# TM4C129ENCPDT register map
File version: 1.0
CPU: CORTEX_M4 1.0, other endian, MPU, FPU, 3 interrupt priority bits
Registers are 32-bit, read-write, reset 0x0 unless marked. A register's access mark holds for its fields unless they carry their own. Offsets are from the block's base; [hi:lo] are bit positions; {n}, {i} and the like mark numbered series.

## USB0 — Univeral Serial Bus register offsets
Base 0x40050000
0x00 USB_FADDR 8-bit — USB Device Functional Address
  [6:0] USB_FADDR — [6:0] Function Address
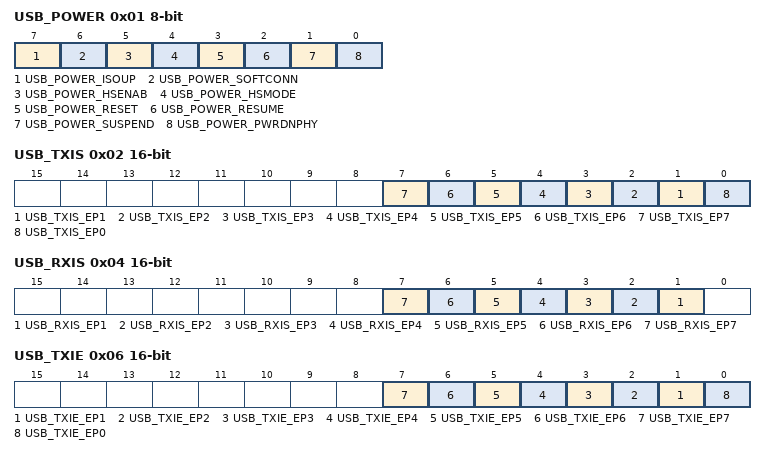
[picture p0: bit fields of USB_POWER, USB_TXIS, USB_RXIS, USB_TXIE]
0x01 USB_POWER 8-bit
  [7] USB_POWER_ISOUP — [7:7] Isochronous Update
  [6] USB_POWER_SOFTCONN — [6:6] Soft Connect/Disconnect
  [5] USB_POWER_HSENAB — [5:5] High Speed Enable
  [4] USB_POWER_HSMODE — [4:4] High Speed Enable
  [3] USB_POWER_RESET — [3:3] RESET Signaling
  [2] USB_POWER_RESUME — [2:2] RESUME Signaling
  [1] USB_POWER_SUSPEND — [1:1] SUSPEND Mode
  [0] USB_POWER_PWRDNPHY — [0:0] Power Down PHY
0x02 USB_TXIS 16-bit — USB Transmit Interrupt Status
  [n] USB_TXIS_EP{n} (n=1..7) — [{n}:{n}] TX Endpoint {n} Interrupt
  [0] USB_TXIS_EP0 — [0:0] TX and RX Endpoint 0 Interrupt
0x04 USB_RXIS 16-bit — USB Receive Interrupt Status
  [n] USB_RXIS_EP{n} (n=1..7) — [{n}:{n}] RX Endpoint {n} Interrupt
0x06 USB_TXIE 16-bit — USB Transmit Interrupt Enable
  [n] USB_TXIE_EP{n} (n=1..7) — [{n}:{n}] TX Endpoint {n} Interrupt Enable
  [0] USB_TXIE_EP0 — [0:0] TX and RX Endpoint 0 Interrupt Enable
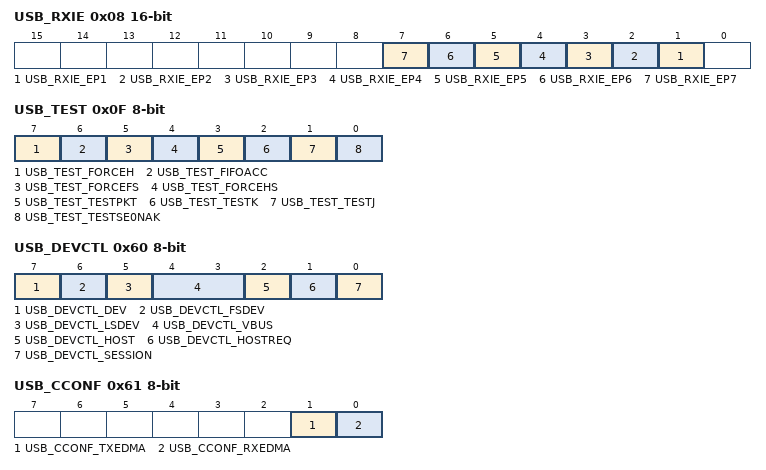
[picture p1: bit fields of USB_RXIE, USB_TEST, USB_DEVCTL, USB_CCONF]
0x08 USB_RXIE 16-bit — USB Receive Interrupt Enable
  [n] USB_RXIE_EP{n} (n=1..7) — [{n}:{n}] RX Endpoint {n} Interrupt Enable
0x0A USB_IS 8-bit — USB General Interrupt Status
  [7] USB_IS_VBUSERR — [7:7] VBUS Error (OTG only)
  [6] USB_IS_SESREQ — [6:6] SESSION REQUEST (OTG only)
  [5] USB_IS_DISCON — [5:5] Session Disconnect (OTG only)
  [4] USB_IS_CONN — [4:4] Session Connect
  [3] USB_IS_SOF — [3:3] Start of Frame
  [2] USB_IS_BABBLE — [2:2] Babble Detected
  [2] USB_IS_RESET — [2:2] RESET Signaling Detected
  [1] USB_IS_RESUME — [1:1] RESUME Signaling Detected
  [0] USB_IS_SUSPEND — [0:0] SUSPEND Signaling Detected
0x0B USB_IE 8-bit — USB Interrupt Enable
  [7] USB_IE_VBUSERR — [7:7] Enable VBUS Error Interrupt (OTG only)
  [6] USB_IE_SESREQ — [6:6] Enable Session Request (OTG only)
  [5] USB_IE_DISCON — [5:5] Enable Disconnect Interrupt
  [4] USB_IE_CONN — [4:4] Enable Connect Interrupt
  [3] USB_IE_SOF — [3:3] Enable Start-of-Frame Interrupt
  [2] USB_IE_BABBLE — [2:2] Enable Babble Interrupt
  [2] USB_IE_RESET — [2:2] Enable RESET Interrupt
  [1] USB_IE_RESUME — [1:1] Enable RESUME Interrupt
  [0] USB_IE_SUSPND — [0:0] Enable SUSPEND Interrupt
0x0C USB_FRAME 16-bit — USB Frame Value
  [10:0] USB_FRAME — [10:0] Frame Number
0x0E USB_EPIDX 8-bit — USB Endpoint Index
  [3:0] USB_EPIDX_EPIDX — [3:0] Endpoint Index
0x0F USB_TEST 8-bit — USB Test Mode
  [7] USB_TEST_FORCEH — [7:7] Force Host Mode
  [6] USB_TEST_FIFOACC — [6:6] FIFO Access
  [5] USB_TEST_FORCEFS — [5:5] Force Full-Speed Mode
  [4] USB_TEST_FORCEHS — [4:4] Force High-Speed Mode
  [3] USB_TEST_TESTPKT — [3:3] Test Packet Mode Enable
  [2] USB_TEST_TESTK — [2:2] Test_K Mode Enable
  [1] USB_TEST_TESTJ — [1:1] Test_J Mode Enable
  [0] USB_TEST_TESTSE0NAK — [0:0] Test_SE0_NAK Test Mode Enable
{0x20+4i} USB_FIFO{i} (i=0..7) — USB FIFO Endpoint {i}
  [31:0] USB_FIFO{i}_EPDATA — [31:0] Endpoint Data
0x60 USB_DEVCTL 8-bit — USB Device Control
  [7] USB_DEVCTL_DEV — [7:7] Device Mode (OTG only)
  [6] USB_DEVCTL_FSDEV — [6:6] Full-Speed Device Detected
  [5] USB_DEVCTL_LSDEV — [5:5] Low-Speed Device Detected
  [4:3] USB_DEVCTL_VBUS — [4:3] VBUS Level (OTG only)
    0=USB_DEVCTL_VBUS_NONE (Below SessionEnd); 8=USB_DEVCTL_VBUS_SEND (Above SessionEnd, below AValid); 16=USB_DEVCTL_VBUS_AVALID (Above AValid, below VBUSValid); 24=USB_DEVCTL_VBUS_VALID (Above VBUSValid)
  [2] USB_DEVCTL_HOST — [2:2] Host Mode
  [1] USB_DEVCTL_HOSTREQ — [1:1] Host Request (OTG only)
  [0] USB_DEVCTL_SESSION — [0:0] Session Start/End (OTG only)
0x61 USB_CCONF 8-bit — USB Common Configuration
  [1] USB_CCONF_TXEDMA — [1:1] TX Early DMA Enable
  [0] USB_CCONF_RXEDMA — [0:0] TX Early DMA Enable
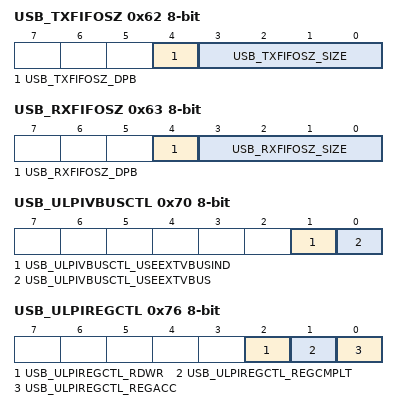
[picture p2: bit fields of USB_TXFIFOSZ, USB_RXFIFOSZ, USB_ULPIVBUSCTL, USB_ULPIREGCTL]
0x62 USB_TXFIFOSZ 8-bit — USB Transmit Dynamic FIFO Sizing
  [4] USB_TXFIFOSZ_DPB — [4:4] Double Packet Buffer Support
  [3:0] USB_TXFIFOSZ_SIZE — [3:0] Max Packet Size
    0=8; 1=16; 2=32; 3=64; 4=128; 5=256; 6=512; 7=1024; 8=2048
0x63 USB_RXFIFOSZ 8-bit — USB Receive Dynamic FIFO Sizing
  [4] USB_RXFIFOSZ_DPB — [4:4] Double Packet Buffer Support
  [3:0] USB_RXFIFOSZ_SIZE — [3:0] Max Packet Size
    0=8; 1=16; 2=32; 3=64; 4=128; 5=256; 6=512; 7=1024; 8=2048
0x64 USB_TXFIFOADD 16-bit — USB Transmit FIFO Start Address
  [8:0] USB_TXFIFOADD_ADDR — [8:0] Transmit/Receive Start Address
0x66 USB_RXFIFOADD 16-bit — USB Receive FIFO Start Address
  [8:0] USB_RXFIFOADD_ADDR — [8:0] Transmit/Receive Start Address
0x70 USB_ULPIVBUSCTL 8-bit — USB ULPI VBUS Control
  [1] USB_ULPIVBUSCTL_USEEXTVBUSIND — [1:1] Use External VBUS Indicator
  [0] USB_ULPIVBUSCTL_USEEXTVBUS — [0:0] Use External VBUS
0x74 USB_ULPIREGDATA 8-bit — USB ULPI Register Data
  [7:0] USB_ULPIREGDATA_REGDATA — [7:0] Register Data
0x75 USB_ULPIREGADDR 8-bit — USB ULPI Register Address
  [7:0] USB_ULPIREGADDR_ADDR — [7:0] Register Address
0x76 USB_ULPIREGCTL 8-bit — USB ULPI Register Control
  [2] USB_ULPIREGCTL_RDWR — [2:2] Read/Write Control
  [1] USB_ULPIREGCTL_REGCMPLT — [1:1] Register Access Complete
  [0] USB_ULPIREGCTL_REGACC — [0:0] Initiate Register Access
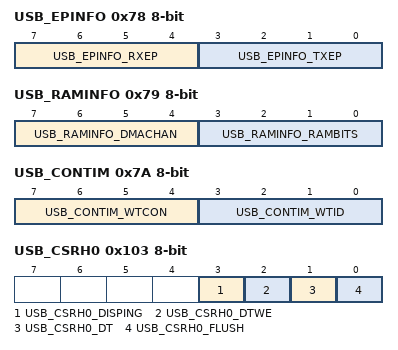
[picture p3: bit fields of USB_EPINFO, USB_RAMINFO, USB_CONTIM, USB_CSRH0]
0x78 USB_EPINFO 8-bit — USB Endpoint Information
  [7:4] USB_EPINFO_RXEP — [7:4] RX Endpoints
  [3:0] USB_EPINFO_TXEP — [3:0] TX Endpoints
0x79 USB_RAMINFO 8-bit — USB RAM Information
  [7:4] USB_RAMINFO_DMACHAN — [7:4] DMA Channels
  [3:0] USB_RAMINFO_RAMBITS — [3:0] RAM Address Bus Width
0x7A USB_CONTIM 8-bit — USB Connect Timing
  [7:4] USB_CONTIM_WTCON — [7:4] Connect Wait
  [3:0] USB_CONTIM_WTID — [3:0] Wait ID
0x7B USB_VPLEN 8-bit — USB OTG VBUS Pulse Timing
  [7:0] USB_VPLEN_VPLEN — [7:0] VBUS Pulse Length
0x7C USB_HSEOF 8-bit — USB High-Speed Last Transaction to End of Frame Timing
  [7:0] USB_HSEOF_HSEOFG — [7:0] HIgh-Speed End-of-Frame Gap
0x7D USB_FSEOF 8-bit — USB Full-Speed Last Transaction to End of Frame Timing
  [7:0] USB_FSEOF_FSEOFG — [7:0] Full-Speed End-of-Frame Gap
0x7E USB_LSEOF 8-bit — USB Low-Speed Last Transaction to End of Frame Timing
  [7:0] USB_LSEOF_LSEOFG — [7:0] Low-Speed End-of-Frame Gap
{0x80+8i} USB_TXFUNCADDR{i} 8-bit (i=0..7) — USB Transmit Functional Address Endpoint {i}
  [6:0] USB_TXFUNCADDR{i}_ADDR — [6:0] Device Address
{0x82+8i} USB_TXHUBADDR{i} 8-bit (i=0..7) — USB Transmit Hub Address Endpoint {i}
  [6:0] USB_TXHUBADDR{i}_ADDR — [6:0] Hub Address
{0x83+8i} USB_TXHUBPORT{i} 8-bit (i=0..7) — USB Transmit Hub Port Endpoint {i}
  [6:0] USB_TXHUBPORT{i}_PORT — [6:0] Hub Port
{0x84+8i} USB_RXFUNCADDR{i} 8-bit (i=1..7) — USB Receive Functional Address Endpoint {i}
  [6:0] USB_RXFUNCADDR{i}_ADDR — [6:0] Device Address
{0x86+8i} USB_RXHUBADDR{i} 8-bit (i=1..7) — USB Receive Hub Address Endpoint {i}
  [6:0] USB_RXHUBADDR{i}_ADDR — [6:0] Hub Address
{0x87+8i} USB_RXHUBPORT{i} 8-bit (i=1..7) — USB Receive Hub Port Endpoint {i}
  [6:0] USB_RXHUBPORT{i}_PORT — [6:0] Hub Port
0x102 USB_CSRL0 8-bit — USB Control and Status Endpoint 0 Low
  [7] USB_CSRL0_NAKTO — [7:7] NAK Timeout
  [7] USB_CSRL0_SETENDC — [7:7] Setup End Clear
  [6] USB_CSRL0_STATUS — [6:6] STATUS Packet
  [6] USB_CSRL0_RXRDYC — [6:6] RXRDY Clear
  [5] USB_CSRL0_REQPKT — [5:5] Request Packet
  [5] USB_CSRL0_STALL — [5:5] Send Stall
  [4] USB_CSRL0_SETEND — [4:4] Setup End
  [4] USB_CSRL0_ERROR — [4:4] Error
  [3] USB_CSRL0_DATAEND — [3:3] Data End
  [3] USB_CSRL0_SETUP — [3:3] Setup Packet
  [2] USB_CSRL0_STALLED — [2:2] Endpoint Stalled
  [1] USB_CSRL0_TXRDY — [1:1] Transmit Packet Ready
  [0] USB_CSRL0_RXRDY — [0:0] Receive Packet Ready
0x103 USB_CSRH0 8-bit — USB Control and Status Endpoint 0 High
  [3] USB_CSRH0_DISPING — [3:3] PING Disable
  [2] USB_CSRH0_DTWE — [2:2] Data Toggle Write Enable
  [1] USB_CSRH0_DT — [1:1] Data Toggle
  [0] USB_CSRH0_FLUSH — [0:0] Flush FIFO
0x108 USB_COUNT0 8-bit — USB Receive Byte Count Endpoint 0
  [6:0] USB_COUNT0_COUNT — [6:0] FIFO Count
0x10A USB_TYPE0 8-bit — USB Type Endpoint 0
  [7:6] USB_TYPE0_SPEED — [7:6] Operating Speed
    64=USB_TYPE0_SPEED_HIGH (High); 128=USB_TYPE0_SPEED_FULL (Full); 192=USB_TYPE0_SPEED_LOW (Low)
0x10B USB_NAKLMT 8-bit — USB NAK Limit
  [4:0] USB_NAKLMT_NAKLMT — [4:0] EP0 NAK Limit
{0x100+0x10*i} USB_TXMAXP{i} 16-bit (i=1..7) — USB Maximum Transmit Data Endpoint {i}
  [10:0] USB_TXMAXP{i}_MAXLOAD — [10:0] Maximum Payload
0x112 USB_TXCSRL1 8-bit — USB Transmit Control and Status Endpoint 1 Low
  [7] USB_TXCSRL1_NAKTO — [7:7] NAK Timeout
  [6] USB_TXCSRL1_CLRDT — [6:6] Clear Data Toggle
  [5] USB_TXCSRL1_STALLED — [5:5] Endpoint Stalled
  [4] USB_TXCSRL1_STALL — [4:4] Send STALL
  [4] USB_TXCSRL1_SETUP — [4:4] Setup Packet
  [3] USB_TXCSRL1_FLUSH — [3:3] Flush FIFO
  [2] USB_TXCSRL1_ERROR — [2:2] Error
  [2] USB_TXCSRL1_UNDRN — [2:2] Underrun
  [1] USB_TXCSRL1_FIFONE — [1:1] FIFO Not Empty
  [0] USB_TXCSRL1_TXRDY — [0:0] Transmit Packet Ready
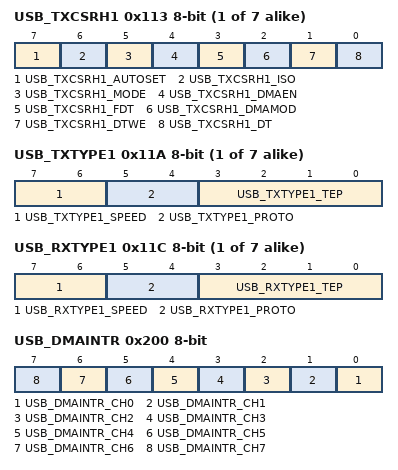
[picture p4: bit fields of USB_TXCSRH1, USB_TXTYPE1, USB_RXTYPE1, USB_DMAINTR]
{0x103+0x10*i} USB_TXCSRH{i} 8-bit (i=1..7) — USB Transmit Control and Status Endpoint {i} High
  [7] USB_TXCSRH{i}_AUTOSET — [7:7] Auto Set
  [6] USB_TXCSRH{i}_ISO — [6:6] Isochronous Transfers
  [5] USB_TXCSRH{i}_MODE — [5:5] Mode
  [4] USB_TXCSRH{i}_DMAEN — [4:4] DMA Request Enable
  [3] USB_TXCSRH{i}_FDT — [3:3] Force Data Toggle
  [2] USB_TXCSRH{i}_DMAMOD — [2:2] DMA Request Mode
  [1] USB_TXCSRH{i}_DTWE — [1:1] Data Toggle Write Enable
  [0] USB_TXCSRH{i}_DT — [0:0] Data Toggle
{0x104+0x10*i} USB_RXMAXP{i} 16-bit (i=1..7) — USB Maximum Receive Data Endpoint {i}
  [10:0] USB_RXMAXP{i}_MAXLOAD — [10:0] Maximum Payload
0x116 USB_RXCSRL1 8-bit — USB Receive Control and Status Endpoint 1 Low
  [7] USB_RXCSRL1_CLRDT — [7:7] Clear Data Toggle
  [6] USB_RXCSRL1_STALLED — [6:6] Endpoint Stalled
  [5] USB_RXCSRL1_STALL — [5:5] Send STALL
  [5] USB_RXCSRL1_REQPKT — [5:5] Request Packet
  [4] USB_RXCSRL1_FLUSH — [4:4] Flush FIFO
  [3] USB_RXCSRL1_DATAERR — [3:3] Data Error
  [3] USB_RXCSRL1_NAKTO — [3:3] NAK Timeout
  [2] USB_RXCSRL1_OVER — [2:2] Overrun
  [2] USB_RXCSRL1_ERROR — [2:2] Error
  [1] USB_RXCSRL1_FULL — [1:1] FIFO Full
  [0] USB_RXCSRL1_RXRDY — [0:0] Receive Packet Ready
{0x107+0x10*i} USB_RXCSRH{i} 8-bit (i=1..6) — USB Receive Control and Status Endpoint {i} High
  [7] USB_RXCSRH{i}_AUTOCL — [7:7] Auto Clear
  [6] USB_RXCSRH{i}_AUTORQ — [6:6] Auto Request
  [6] USB_RXCSRH{i}_ISO — [6:6] Isochronous Transfers
  [5] USB_RXCSRH{i}_DMAEN — [5:5] DMA Request Enable
  [4] USB_RXCSRH{i}_DISNYET — [4:4] Disable NYET
  [4] USB_RXCSRH{i}_PIDERR — [4:4] PID Error
  [3] USB_RXCSRH{i}_DMAMOD — [3:3] DMA Request Mode
  [2] USB_RXCSRH{i}_DTWE — [2:2] Data Toggle Write Enable
  [1] USB_RXCSRH{i}_DT — [1:1] Data Toggle
  [0] USB_RXCSRH{i}_INCOMPRX — [0:0] Incomplete RX Transmission Status
{0x108+0x10*i} USB_RXCOUNT{i} 16-bit (i=1..7) — USB Receive Byte Count Endpoint {i}
  [12:0] USB_RXCOUNT{i}_COUNT — [12:0] Receive Packet Count
{0x10A+0x10*i} USB_TXTYPE{i} 8-bit (i=1..7) — USB Host Transmit Configure Type Endpoint {i}
  [7:6] USB_TXTYPE{i}_SPEED — [7:6] Operating Speed
    0=USB_TXTYPE{i}_SPEED_DFLT (Default); 64=USB_TXTYPE{i}_SPEED_HIGH (High); 128=USB_TXTYPE{i}_SPEED_FULL (Full); 192=USB_TXTYPE{i}_SPEED_LOW (Low)
  [5:4] USB_TXTYPE{i}_PROTO — [5:4] Protocol
    0=USB_TXTYPE{i}_PROTO_CTRL (Control); 16=USB_TXTYPE{i}_PROTO_ISOC (Isochronous); 32=USB_TXTYPE{i}_PROTO_BULK (Bulk); 48=USB_TXTYPE{i}_PROTO_INT (Interrupt)
  [3:0] USB_TXTYPE{i}_TEP — [3:0] Target Endpoint Number
{0x10B+0x10*i} USB_TXINTERVAL{i} 8-bit (i=1..7) — USB Host Transmit Interval Endpoint {i}
  [7:0] USB_TXINTERVAL{i}_TXPOLL — [7:0] TX Polling
{0x10B+0x10*i} USB_TXINTERVAL{i}_ 8-bit (i=1..7) — USB Host Transmit Interval Endpoint {i}
  [7:0] USB_TXINTERVAL{i}_NAKLMT — [7:0] NAK Limit
{0x10C+0x10*i} USB_RXTYPE{i} 8-bit (i=1..7) — USB Host Configure Receive Type Endpoint {i}
  [7:6] USB_RXTYPE{i}_SPEED — [7:6] Operating Speed
    0=USB_RXTYPE{i}_SPEED_DFLT (Default); 64=USB_RXTYPE{i}_SPEED_HIGH (High); 128=USB_RXTYPE{i}_SPEED_FULL (Full); 192=USB_RXTYPE{i}_SPEED_LOW (Low)
  [5:4] USB_RXTYPE{i}_PROTO — [5:4] Protocol
    0=USB_RXTYPE{i}_PROTO_CTRL (Control); 16=USB_RXTYPE{i}_PROTO_ISOC (Isochronous); 32=USB_RXTYPE{i}_PROTO_BULK (Bulk); 48=USB_RXTYPE{i}_PROTO_INT (Interrupt)
  [3:0] USB_RXTYPE{i}_TEP — [3:0] Target Endpoint Number
{0x10D+0x10*i} USB_RXINTERVAL{i} 8-bit (i=1..7) — USB Host Receive Polling Interval Endpoint {i}
  [7:0] USB_RXINTERVAL{i}_TXPOLL — [7:0] RX Polling
{0x10D+0x10*i} USB_RXINTERVAL{i}_ 8-bit (i=1..7) — USB Host Receive Polling Interval Endpoint {i}
  [7:0] USB_RXINTERVAL{i}_NAKLMT — [7:0] NAK Limit
{0x102+0x10*i} USB_TXCSRL{i} 8-bit (i=2..5) — USB Transmit Control and Status Endpoint {i} Low
  [7] USB_TXCSRL{i}_NAKTO — [7:7] NAK Timeout
  [6] USB_TXCSRL{i}_CLRDT — [6:6] Clear Data Toggle
  [5] USB_TXCSRL{i}_STALLED — [5:5] Endpoint Stalled
  [4] USB_TXCSRL{i}_SETUP — [4:4] Setup Packet
  [4] USB_TXCSRL{i}_STALL — [4:4] Send STALL
  [3] USB_TXCSRL{i}_FLUSH — [3:3] Flush FIFO
  [2] USB_TXCSRL{i}_ERROR — [2:2] Error
  [2] USB_TXCSRL{i}_UNDRN — [2:2] Underrun
  [1] USB_TXCSRL{i}_FIFONE — [1:1] FIFO Not Empty
  [0] USB_TXCSRL{i}_TXRDY — [0:0] Transmit Packet Ready
0x126 USB_RXCSRL2 8-bit — USB Receive Control and Status Endpoint 2 Low
  [7] USB_RXCSRL2_CLRDT — [7:7] Clear Data Toggle
  [6] USB_RXCSRL2_STALLED — [6:6] Endpoint Stalled
  [5] USB_RXCSRL2_REQPKT — [5:5] Request Packet
  [5] USB_RXCSRL2_STALL — [5:5] Send STALL
  [4] USB_RXCSRL2_FLUSH — [4:4] Flush FIFO
  [3] USB_RXCSRL2_DATAERR — [3:3] Data Error
  [3] USB_RXCSRL2_NAKTO — [3:3] NAK Timeout
  [2] USB_RXCSRL2_ERROR — [2:2] Error
  [2] USB_RXCSRL2_OVER — [2:2] Overrun
  [1] USB_RXCSRL2_FULL — [1:1] FIFO Full
  [0] USB_RXCSRL2_RXRDY — [0:0] Receive Packet Ready
0x136 USB_RXCSRL3 8-bit — USB Receive Control and Status Endpoint 3 Low
  [7] USB_RXCSRL3_CLRDT — [7:7] Clear Data Toggle
  [6] USB_RXCSRL3_STALLED — [6:6] Endpoint Stalled
  [5] USB_RXCSRL3_STALL — [5:5] Send STALL
  [5] USB_RXCSRL3_REQPKT — [5:5] Request Packet
  [4] USB_RXCSRL3_FLUSH — [4:4] Flush FIFO
  [3] USB_RXCSRL3_DATAERR — [3:3] Data Error
  [3] USB_RXCSRL3_NAKTO — [3:3] NAK Timeout
  [2] USB_RXCSRL3_ERROR — [2:2] Error
  [2] USB_RXCSRL3_OVER — [2:2] Overrun
  [1] USB_RXCSRL3_FULL — [1:1] FIFO Full
  [0] USB_RXCSRL3_RXRDY — [0:0] Receive Packet Ready
0x146 USB_RXCSRL4 8-bit — USB Receive Control and Status Endpoint 4 Low
  [7] USB_RXCSRL4_CLRDT — [7:7] Clear Data Toggle
  [6] USB_RXCSRL4_STALLED — [6:6] Endpoint Stalled
  [5] USB_RXCSRL4_STALL — [5:5] Send STALL
  [5] USB_RXCSRL4_REQPKT — [5:5] Request Packet
  [4] USB_RXCSRL4_FLUSH — [4:4] Flush FIFO
  [3] USB_RXCSRL4_NAKTO — [3:3] NAK Timeout
  [3] USB_RXCSRL4_DATAERR — [3:3] Data Error
  [2] USB_RXCSRL4_OVER — [2:2] Overrun
  [2] USB_RXCSRL4_ERROR — [2:2] Error
  [1] USB_RXCSRL4_FULL — [1:1] FIFO Full
  [0] USB_RXCSRL4_RXRDY — [0:0] Receive Packet Ready
0x156 USB_RXCSRL5 8-bit — USB Receive Control and Status Endpoint 5 Low
  [7] USB_RXCSRL5_CLRDT — [7:7] Clear Data Toggle
  [6] USB_RXCSRL5_STALLED — [6:6] Endpoint Stalled
  [5] USB_RXCSRL5_STALL — [5:5] Send STALL
  [5] USB_RXCSRL5_REQPKT — [5:5] Request Packet
  [4] USB_RXCSRL5_FLUSH — [4:4] Flush FIFO
  [3] USB_RXCSRL5_NAKTO — [3:3] NAK Timeout
  [3] USB_RXCSRL5_DATAERR — [3:3] Data Error
  [2] USB_RXCSRL5_ERROR — [2:2] Error
  [2] USB_RXCSRL5_OVER — [2:2] Overrun
  [1] USB_RXCSRL5_FULL — [1:1] FIFO Full
  [0] USB_RXCSRL5_RXRDY — [0:0] Receive Packet Ready
0x162 USB_TXCSRL6 8-bit — USB Transmit Control and Status Endpoint 6 Low
  [7] USB_TXCSRL6_NAKTO — [7:7] NAK Timeout
  [6] USB_TXCSRL6_CLRDT — [6:6] Clear Data Toggle
  [5] USB_TXCSRL6_STALLED — [5:5] Endpoint Stalled
  [4] USB_TXCSRL6_STALL — [4:4] Send STALL
  [4] USB_TXCSRL6_SETUP — [4:4] Setup Packet
  [3] USB_TXCSRL6_FLUSH — [3:3] Flush FIFO
  [2] USB_TXCSRL6_ERROR — [2:2] Error
  [2] USB_TXCSRL6_UNDRN — [2:2] Underrun
  [1] USB_TXCSRL6_FIFONE — [1:1] FIFO Not Empty
  [0] USB_TXCSRL6_TXRDY — [0:0] Transmit Packet Ready
0x166 USB_RXCSRL6 8-bit — USB Receive Control and Status Endpoint 6 Low
  [7] USB_RXCSRL6_CLRDT — [7:7] Clear Data Toggle
  [6] USB_RXCSRL6_STALLED — [6:6] Endpoint Stalled
  [5] USB_RXCSRL6_REQPKT — [5:5] Request Packet
  [5] USB_RXCSRL6_STALL — [5:5] Send STALL
  [4] USB_RXCSRL6_FLUSH — [4:4] Flush FIFO
  [3] USB_RXCSRL6_NAKTO — [3:3] NAK Timeout
  [3] USB_RXCSRL6_DATAERR — [3:3] Data Error
  [2] USB_RXCSRL6_ERROR — [2:2] Error
  [2] USB_RXCSRL6_OVER — [2:2] Overrun
  [1] USB_RXCSRL6_FULL — [1:1] FIFO Full
  [0] USB_RXCSRL6_RXRDY — [0:0] Receive Packet Ready
0x172 USB_TXCSRL7 8-bit — USB Transmit Control and Status Endpoint 7 Low
  [7] USB_TXCSRL7_NAKTO — [7:7] NAK Timeout
  [6] USB_TXCSRL7_CLRDT — [6:6] Clear Data Toggle
  [5] USB_TXCSRL7_STALLED — [5:5] Endpoint Stalled
  [4] USB_TXCSRL7_STALL — [4:4] Send STALL
  [4] USB_TXCSRL7_SETUP — [4:4] Setup Packet
  [3] USB_TXCSRL7_FLUSH — [3:3] Flush FIFO
  [2] USB_TXCSRL7_ERROR — [2:2] Error
  [2] USB_TXCSRL7_UNDRN — [2:2] Underrun
  [1] USB_TXCSRL7_FIFONE — [1:1] FIFO Not Empty
  [0] USB_TXCSRL7_TXRDY — [0:0] Transmit Packet Ready
0x176 USB_RXCSRL7 8-bit — USB Receive Control and Status Endpoint 7 Low
  [7] USB_RXCSRL7_CLRDT — [7:7] Clear Data Toggle
  [6] USB_RXCSRL7_STALLED — [6:6] Endpoint Stalled
  [5] USB_RXCSRL7_REQPKT — [5:5] Request Packet
  [5] USB_RXCSRL7_STALL — [5:5] Send STALL
  [4] USB_RXCSRL7_FLUSH — [4:4] Flush FIFO
  [3] USB_RXCSRL7_DATAERR — [3:3] Data Error
  [3] USB_RXCSRL7_NAKTO — [3:3] NAK Timeout
  [2] USB_RXCSRL7_ERROR — [2:2] Error
  [2] USB_RXCSRL7_OVER — [2:2] Overrun
  [1] USB_RXCSRL7_FULL — [1:1] FIFO Full
  [0] USB_RXCSRL7_RXRDY — [0:0] Receive Packet Ready
0x177 USB_RXCSRH7 8-bit — USB Receive Control and Status Endpoint 7 High
  [7] USB_RXCSRH7_AUTOCL — [7:7] Auto Clear
  [6] USB_RXCSRH7_ISO — [6:6] Isochronous Transfers
  [6] USB_RXCSRH7_AUTORQ — [6:6] Auto Request
  [5] USB_RXCSRH7_DMAEN — [5:5] DMA Request Enable
  [4] USB_RXCSRH7_PIDERR — [4:4] PID Error
  [4] USB_RXCSRH7_DISNYET — [4:4] Disable NYET
  [3] USB_RXCSRH7_DMAMOD — [3:3] DMA Request Mode
  [2] USB_RXCSRH7_DTWE — [2:2] Data Toggle Write Enable
  [1] USB_RXCSRH7_DT — [1:1] Data Toggle
  [0] USB_RXCSRH7_INCOMPRX — [0:0] Incomplete RX Transmission Status
0x200 USB_DMAINTR 8-bit — USB DMA Interrupt
  [n] USB_DMAINTR_CH{n} (n=0..7) — [{n}:{n}] Channel {n} DMA Interrupt
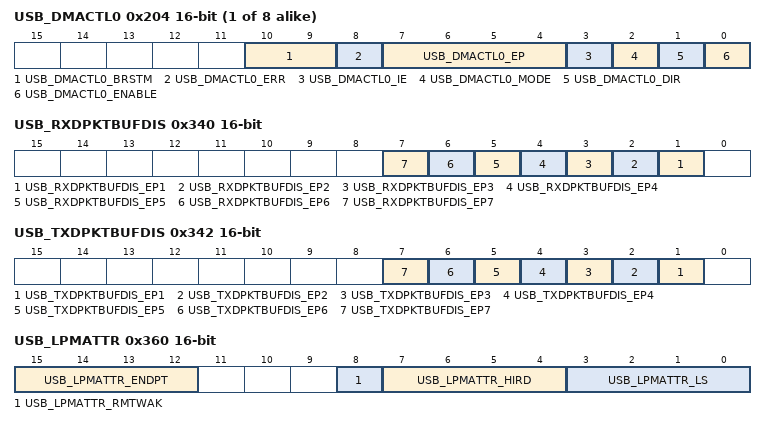
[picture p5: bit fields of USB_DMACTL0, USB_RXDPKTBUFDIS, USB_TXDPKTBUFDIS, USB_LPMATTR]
{0x204+0x10*i} USB_DMACTL{i} 16-bit (i=0..7) — USB DMA Control {i}
  [10:9] USB_DMACTL{i}_BRSTM — [10:9] Burst Mode
    0=USB_DMACTL{i}_BRSTM_ANY (Bursts of unspecified length); 0x200=USB_DMACTL{i}_BRSTM_INC4 (INCR4 or unspecified length); 0x400=USB_DMACTL{i}_BRSTM_INC8 (INCR8, INCR4 or unspecified length); 0x600=USB_DMACTL{i}_BRSTM_INC16 (INCR16, INCR8, INCR4 or unspecified length)
  [8] USB_DMACTL{i}_ERR — [8:8] Bus Error Bit
  [7:4] USB_DMACTL{i}_EP — [7:4] Endpoint number
  [3] USB_DMACTL{i}_IE — [3:3] DMA Interrupt Enable
  [2] USB_DMACTL{i}_MODE — [2:2] DMA Transfer Mode
  [1] USB_DMACTL{i}_DIR — [1:1] DMA Direction
  [0] USB_DMACTL{i}_ENABLE — [0:0] DMA Transfer Enable
{0x208+0x10*i} USB_DMAADDR{i} (i=0..7) — USB DMA Address {i}
  [31:2] USB_DMAADDR{i}_ADDR — [31:2] DMA Address
{0x20C+0x10*i} USB_DMACOUNT{i} (i=0..7)
  [31:2] USB_DMACOUNT{i}_COUNT — [31:2] DMA Count
{0x300+4i} USB_RQPKTCOUNT{i} 16-bit (i=1..3) — USB Request Packet Count in Block Transfer Endpoint {i}
  [15:0] USB_RQPKTCOUNT{i} — [15:0] Block Transfer Packet Count
{0x300+4i} USB_RQPKTCOUNT{i} 16-bit (i=4..7) — USB Request Packet Count in Block Transfer Endpoint {i}
  [15:0] USB_RQPKTCOUNT{i}_COUNT — [15:0] Block Transfer Packet Count
0x340 USB_RXDPKTBUFDIS 16-bit — USB Receive Double Packet Buffer Disable
  [n] USB_RXDPKTBUFDIS_EP{n} (n=1..7) — [{n}:{n}] EP{n} RX Double-Packet Buffer Disable
0x342 USB_TXDPKTBUFDIS 16-bit — USB Transmit Double Packet Buffer Disable
  [n] USB_TXDPKTBUFDIS_EP{n} (n=1..7) — [{n}:{n}] EP{n} TX Double-Packet Buffer Disable
0x344 USB_CTO 16-bit — USB Chirp Timeout
  [15:0] USB_CTO_CCTV — [15:0] Configurable Chirp Timeout Value
0x346 USB_HHSRTN 16-bit — USB High Speed to UTM Operating Delay
  [15:0] USB_HHSRTN_HHSRTN — [15:0] HIgh Speed to UTM Operating Delay
0x348 USB_HSBT 16-bit — USB High Speed Time-out Adder
  [3:0] USB_HSBT_HSBT — [3:0] High Speed Timeout Adder
0x360 USB_LPMATTR 16-bit — USB LPM Attributes
  [15:12] USB_LPMATTR_ENDPT — [15:12] Endpoint
  [8] USB_LPMATTR_RMTWAK — [8:8] Remote Wake
  [7:4] USB_LPMATTR_HIRD — [7:4] Host Initiated Resume Duration
  [3:0] USB_LPMATTR_LS — [3:0] Link State
    1=USB_LPMATTR_LS_L1 (Sleep State (L1))
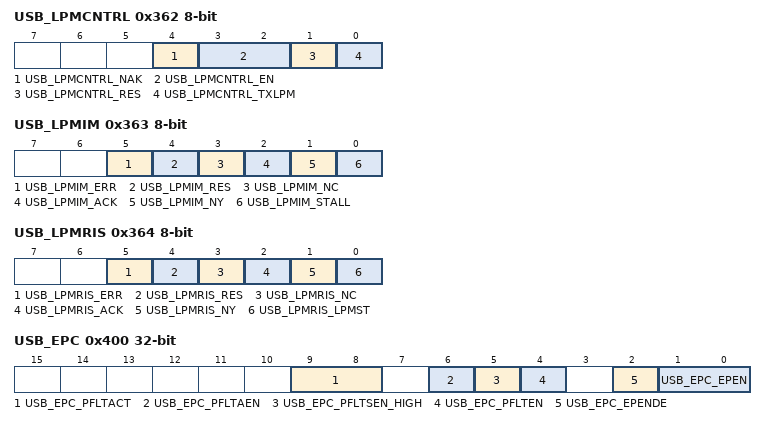
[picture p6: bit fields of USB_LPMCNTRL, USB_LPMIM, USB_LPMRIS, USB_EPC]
0x362 USB_LPMCNTRL 8-bit — USB LPM Control
  [4] USB_LPMCNTRL_NAK — [4:4] LPM NAK
  [3:2] USB_LPMCNTRL_EN — [3:2] LPM Enable
    0=USB_LPMCNTRL_EN_NONE (LPM and Extended transactions are not supported. In this case, the USB does not respond to LPM transactions and LPM transactions cause a timeout); 4=USB_LPMCNTRL_EN_EXT (LPM is not supported but extended transactions are supported. In this case, the USB does respond to an LPM transaction with a STALL); 12=USB_LPMCNTRL_EN_LPMEXT (The USB supports LPM extended transactions. In this case, the USB responds with a NYET or an ACK as determined by the value of TXLPM and other conditions)
  [1] USB_LPMCNTRL_RES — [1:1] LPM Resume
  [0] USB_LPMCNTRL_TXLPM — [0:0] Transmit LPM Transaction Enable
0x363 USB_LPMIM 8-bit — USB LPM Interrupt Mask
  [5] USB_LPMIM_ERR — [5:5] LPM Error Interrupt Mask
  [4] USB_LPMIM_RES — [4:4] LPM Resume Interrupt Mask
  [3] USB_LPMIM_NC — [3:3] LPM NC Interrupt Mask
  [2] USB_LPMIM_ACK — [2:2] LPM ACK Interrupt Mask
  [1] USB_LPMIM_NY — [1:1] LPM NY Interrupt Mask
  [0] USB_LPMIM_STALL — [0:0] LPM STALL Interrupt Mask
0x364 USB_LPMRIS 8-bit — USB LPM Raw Interrupt Status
  [5] USB_LPMRIS_ERR — [5:5] LPM Interrupt Status
  [4] USB_LPMRIS_RES — [4:4] LPM Resume Interrupt Status
  [3] USB_LPMRIS_NC — [3:3] LPM NC Interrupt Status
  [2] USB_LPMRIS_ACK — [2:2] LPM ACK Interrupt Status
  [1] USB_LPMRIS_NY — [1:1] LPM NY Interrupt Status
  [0] USB_LPMRIS_LPMST — [0:0] LPM STALL Interrupt Status
0x365 USB_LPMFADDR 8-bit — USB LPM Function Address
  [6:0] USB_LPMFADDR_ADDR — [6:0] LPM Function Address
0x400 USB_EPC — USB External Power Control
  [9:8] USB_EPC_PFLTACT — [9:8] Power Fault Action
    0=USB_EPC_PFLTACT_UNCHG (Unchanged); 0x100=USB_EPC_PFLTACT_TRIS (Tristate); 0x200=USB_EPC_PFLTACT_LOW (Low); 0x300=USB_EPC_PFLTACT_HIGH (High)
  [6] USB_EPC_PFLTAEN — [6:6] Power Fault Action Enable
  [5] USB_EPC_PFLTSEN_HIGH — [5:5] Power Fault Sense
  [4] USB_EPC_PFLTEN — [4:4] Power Fault Input Enable
  [2] USB_EPC_EPENDE — [2:2] EPEN Drive Enable
  [1:0] USB_EPC_EPEN — [1:0] External Power Supply Enable Configuration
    0=USB_EPC_EPEN_LOW (Power Enable Active Low); 1=USB_EPC_EPEN_HIGH (Power Enable Active High); 2=USB_EPC_EPEN_VBLOW (Power Enable High if VBUS Low (OTG only)); 3=USB_EPC_EPEN_VBHIGH (Power Enable High if VBUS High (OTG only))
0x404 USB_EPCRIS — USB External Power Control Raw Interrupt Status
  [0] USB_EPCRIS_PF — [0:0] USB Power Fault Interrupt Status
0x408 USB_EPCIM — USB External Power Control Interrupt Mask
  [0] USB_EPCIM_PF — [0:0] USB Power Fault Interrupt Mask
0x40C USB_EPCISC — USB External Power Control Interrupt Status and Clear
  [0] USB_EPCISC_PF — [0:0] USB Power Fault Interrupt Status and Clear
0x410 USB_DRRIS — USB Device RESUME Raw Interrupt Status
  [0] USB_DRRIS_RESUME — [0:0] RESUME Interrupt Status
0x414 USB_DRIM — USB Device RESUME Interrupt Mask
  [0] USB_DRIM_RESUME — [0:0] RESUME Interrupt Mask
0x418 USB_DRISC — USB Device RESUME Interrupt Status and Clear
  [0] USB_DRISC_RESUME — [0:0] RESUME Interrupt Status and Clear
0x41C USB_GPCS — USB General-Purpose Control and Status
  [2:0] USB_GPCS_DEVMOD — [2:0] Device Mode
    0=USB_GPCS_DEVMOD_OTG (Use USB0VBUS and USB0ID pin); 2=USB_GPCS_DEVMOD_HOST (Force USB0VBUS and USB0ID low); 3=USB_GPCS_DEVMOD_DEV (Force USB0VBUS and USB0ID high); 4=USB_GPCS_DEVMOD_HOSTVBUS (Use USB0VBUS and force USB0ID low); 5=USB_GPCS_DEVMOD_DEVVBUS (Use USB0VBUS and force USB0ID high)
0x430 USB_VDC — USB VBUS Droop Control
  [0] USB_VDC_VBDEN — [0:0] VBUS Droop Enable
0x434 USB_VDCRIS — USB VBUS Droop Control Raw Interrupt Status
  [0] USB_VDCRIS_VD — [0:0] VBUS Droop Raw Interrupt Status
0x438 USB_VDCIM — USB VBUS Droop Control Interrupt Mask
  [0] USB_VDCIM_VD — [0:0] VBUS Droop Interrupt Mask
0x43C USB_VDCISC — USB VBUS Droop Control Interrupt Status and Clear
  [0] USB_VDCISC_VD — [0:0] VBUS Droop Interrupt Status and Clear
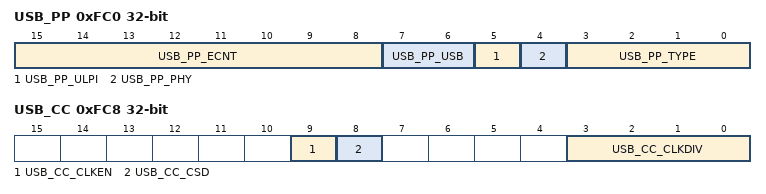
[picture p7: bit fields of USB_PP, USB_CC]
0xFC0 USB_PP — USB Peripheral Properties
  [15:8] USB_PP_ECNT — [15:8] Endpoint Count
  [7:6] USB_PP_USB — [7:6] USB Capability
    64=USB_PP_USB_DEVICE (DEVICE); 128=USB_PP_USB_HOSTDEVICE (HOST); 192=USB_PP_USB_OTG (OTG)
  [5] USB_PP_ULPI — [5:5] ULPI Present
  [4] USB_PP_PHY — [4:4] PHY Present
  [3:0] USB_PP_TYPE — [3:0] Controller Type
    0=The first-generation USB controller; 1=Second-generation USB controller.The controller implemented in post Icestorm devices that use the 3.0 version of the Mentor controller
0xFC4 USB_PC — USB Peripheral Configuration
  [16] USB_PC_ULPIEN — [16:16] ULPI Enable
0xFC8 USB_CC — USB Clock Configuration
  [9] USB_CC_CLKEN — [9:9] USB Clock Enable
  [8] USB_CC_CSD — [8:8] Clock Source/Direction
  [3:0] USB_CC_CLKDIV — [3:0] PLL Clock Divisor
